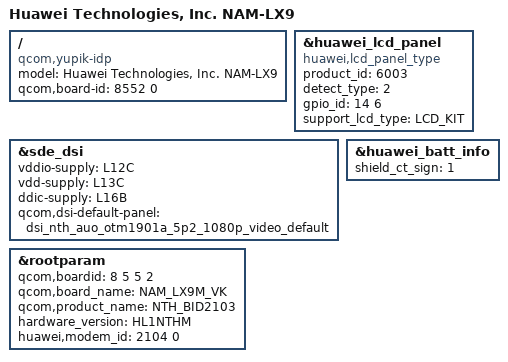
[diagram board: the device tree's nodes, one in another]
/dts-v1/;
/plugin/;

#include "../common/common.dtsi"
#include "huawei-nfc.dtsi"
#include "huawei_camera.dtsi"
#include "huawei_wifi.dtsi"
#include "huawei_dp.dtsi"


/ {
    /* bsp_replace_info @ model = "Huawei Technologies, Inc. %product_name%"; */
    model = "Huawei Technologies, Inc. NAM-LX9";
    compatible = "qcom,yupik-idp", "qcom,yupik", "qcom,idp";
    /* bsp_replace_info @ qcom,board-id = <%boardid% 0>; */
    qcom,board-id = <8552 0>;
};

&huawei_lcd_panel {
	compatible = "huawei,lcd_panel_type";
	/* auto_key_info @ name: product_id type: uint32 default: 0 */
	product_id = <6003>;
	detect_type = <2>;
	/* auto_key_info @ name: gpio_id[2] type: int default: 0 */
	gpio_id = <14 6>;
	support_lcd_type = "LCD_KIT";
};

&sde_dsi {
	vddio-supply = <&L12C>;
	vdd-supply = <&L13C>;
	ddic-supply = <&L16B>;
	qcom,dsi-default-panel = <&dsi_nth_auo_otm1901a_5p2_1080p_video_default>;
};

&rootparam {
    /* bsp_replace_info @ qcom,boardid = <%boardid_split%>; */
    /* auto_key_info @ name: boardid type: uint32 default: 0 */
    qcom,boardid = <8 5 5 2>;
    /* bsp_replace_info @ qcom,board_name = "%board_name%"; */
    qcom,board_name = "NAM_LX9M_VK";
    /* bsp_replace_info @ qcom,product_name = "%product_name%"; */
    qcom,product_name = "NTH_BID2103";
    /* bsp_replace_info @ hardware_version = "%hardware_version%"; */
    hardware_version = "HL1NTHM";
    /* bsp_replace_info @ huawei,modem_id = <%modem_id% 0x0>; */
    huawei,modem_id = <2104 0>;
};

&huawei_batt_info {
	shield_ct_sign = <1>;
};
